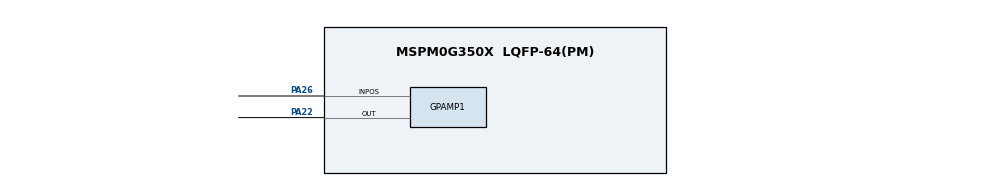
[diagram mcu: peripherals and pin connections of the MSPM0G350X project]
/**
 * @cliArgs --device "MSPM0G350X" --part "Default" --package "LQFP-64(PM)" --product "mspm0_sdk@2.08.00.02"
 * @versions {"tool":"1.25.0+4268"}
 */

/**
 * Import the modules used in this configuration.
 */
const Board         = scripting.addModule("/ti/driverlib/Board");
const GPAMP         = scripting.addModule("/ti/driverlib/GPAMP", {}, false);
const GPAMP1        = GPAMP.addInstance();
const SYSCTL        = scripting.addModule("/ti/driverlib/SYSCTL");
const VREF          = scripting.addModule("/ti/driverlib/VREF");
const ProjectConfig = scripting.addModule("/ti/project_config/ProjectConfig");

/**
 * Write custom configuration values to the imported modules.
 */

GPAMP1.$name                       = "GPAMP_0";
GPAMP1.cfgPSELChannel              = "IN_POS";
GPAMP1.cfgOutputPin                = "ENABLED";
GPAMP1.cfgNSELChannel              = "OUTPUT_PIN";
GPAMP1.InPosPinConfig.$name        = "ti_driverlib_gpio_GPIOPinGeneric0";
GPAMP1.peripheral.$assign          = "GPAMP";
GPAMP1.peripheral.InPosPin.$assign = "PA26";
GPAMP1.peripheral.OutPin.$assign   = "PA22";
GPAMP1.OutPinConfig.$name          = "ti_driverlib_gpio_GPIOPinGeneric1";

SYSCTL.clockTreeEn           = true;
SYSCTL.forceDefaultClkConfig = true;

VREF.basicVrefPins          = "VREF+-";
VREF.basicIntVolt           = "DL_VREF_BUFCONFIG_OUTPUT_2_5V";
VREF.checkVREFReady         = true;
VREF.vrefPosPinConfig.$name = "ti_driverlib_gpio_GPIOPinGeneric2";
VREF.vrefNegPinConfig.$name = "ti_driverlib_gpio_GPIOPinGeneric3";

/**
 * Pinmux solution for unlocked pins/peripherals. This ensures that minor changes to the automatic solver in a future
 * version of the tool will not impact the pinmux you originally saw.  These lines can be completely deleted in order to
 * re-solve from scratch.
 */
Board.peripheral.$suggestSolution           = "DEBUGSS";
Board.peripheral.swclkPin.$suggestSolution  = "PA20";
Board.peripheral.swdioPin.$suggestSolution  = "PA19";
VREF.peripheral.$suggestSolution            = "VREF";
VREF.peripheral.vrefPosPin.$suggestSolution = "PA23";
VREF.peripheral.vrefNegPin.$suggestSolution = "PA21";
